# CC2538NF53 register map
File version: 1.0
CPU: CM3 1.0, other endian, MPU, FPU, 3 interrupt priority bits
Registers are 32-bit, read-write, reset 0x0 unless marked. A register's access mark holds for its fields unless they carry their own. Offsets are from the block's base; [hi:lo] are bit positions; {n}, {i} and the like mark numbered series.

## ANA_REGS — Register fields should be considered static unless otherwise noted as dynamic.
Base 0x400D6000
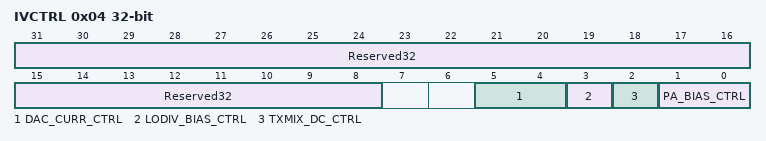
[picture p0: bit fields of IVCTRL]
0x04 IVCTRL — Analog control register
  [31:8] Reserved32 — [31:8] This register is 8 bits in a 32-bit address space.
  [5:4] DAC_CURR_CTRL — [5:4] Controls bias current to DAC 00: 100% IVREF, 0% IREF bias 01: 60% IVREF, 40% IREF bias 10: 40% IVREF, 60% IREF bias 11: 0% IVREF, 100% IREF bias
  [3] LODIV_BIAS_CTRL — [3:3] Controls bias current to LODIV 1: PTAT bias 0: IVREF bias
  [2] TXMIX_DC_CTRL — [2:2] Controls DC bias in TXMIX
  [1:0] PA_BIAS_CTRL — [1:0] Controls bias current to PA 00: IREF bias 01: IREF and IVREF bias (CC2530 mode) 10: PTAT bias 11: Increased PTAT slope bias

## STTEST — Register fields should be considered static unless otherwise noted as dynamic.
Base 0x40110000
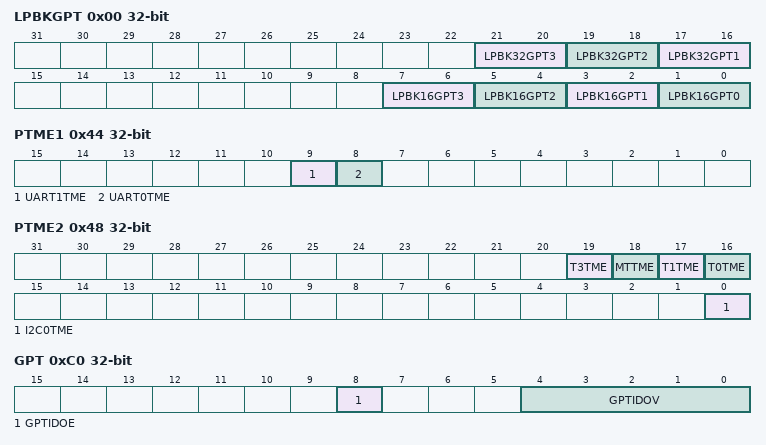
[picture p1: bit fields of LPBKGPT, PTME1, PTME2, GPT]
0x00 LPBKGPT — GPTIMER Internal loopback
  [21:20] LPBK32GPT3 — [21:20] GPTimer3 32-bit RTC loopback modes 00: Normal operation 01: GPT0 GPTimerA PWM connected to GPT3 capture 10: GPT0 capture connected to GPT3 PWM GPTimer A 11: Reserved, defaults to normal operation
  [19:18] LPBK32GPT2 — [19:18] GPTimer2 32-bit RTC loopback modes 00: Normal operation 01: GPT0 Timer A PWM connected to GPT2 capture 10: GPT0 capture connected to GPT2 PWM Timer A 11: Reserved, defaults to normal operation
  [17:16] LPBK32GPT1 — [17:16] GPTimer1 32-bit RTC loopback modes 00: Normal operation 01: GPT0 timerA PWM connected to GPT1 capture 10: GPT0 capture connected to GPT1 PWM Timer A 11: Reserved, defaults to normal operation
  [2n+1:2n] LPBK16GPT{n} (n=0..3) — [{2n+1}:{2n}] GPTimer{n} 16-bit loopback modes 00: Normal operation 01: Timer A PWM connected to Timer B capture 10: Timer A capture connected to Timer B PWM 11: Reserved, defaults to normal operation
0x04 LPBKUART — UART internal loopback
  [0] LPBKUART — [0:0] UART0/1 loopback mode 0: Normal operation 1: UART0 TX (RX) connected to UART1 RX (TX)
0x0C LPBKI2C — I2C internal loopback
  [0] LPBKI2C — [0:0] I2C0 Master/slave loopback mode 0: Normal mode
0x44 PTME1 — Peripheral test mode enable 1
  [9] UART1TME — [9:9] UART1 test mode enable
  [8] UART0TME — [8:8] UART0 test mode enable
0x48 PTME2 — Peripheral test mode enable 2
  [19] T3TME — [19:19] Timer3 test mode enable
  [18] MTTME — [18:18] MacTimer test mode enable
  [17] T1TME — [17:17] Timer1 test mode enable
  [16] T0TME — [16:16] Timer0 test mode enable
  [0] I2C0TME — [0:0] I2C 0 test mode enable
0xC0 GPT — GPTIMER override values
  [8] GPTIDOE — [8:8] GPTimer increment/decrement override enable
  [4:0] GPTIDOV — [4:0] GPTimer increment/decrement override value

## CCTEST — Register fields should be considered static unless otherwise noted as dynamic.
Base 0x44010000
0x00 IO — Output strength control
  [0] SC — [0:0] I/O strength control bit Common to all digital output pads Should be set when unregulated voltage is below approximately 2.6 V.
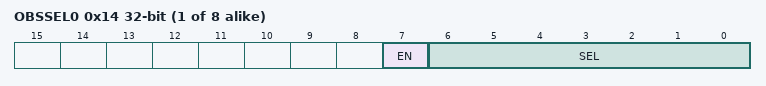
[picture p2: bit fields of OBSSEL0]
{0x14+4i} OBSSEL{i} (i=0..7) — Select output signal on observation output {i}
  [7] EN — [7:7] Observation output {i} enable control for PC{i} 0: Observation output disabled 1: Observation output enabled Note: If enabled, this overwrites the standard GPIO behavior of PC{i}.
  [6:0] SEL — [6:0] n - obs_sigs[n] output on output {i}: 0: rfc_obs_sig0 1: rfc_obs_sig1 2: rfc_obs_sig2 Others: Reserved
0x34 TR0 — Test register 0
  [1] ADCTM — [1:1] Set to 1 to connect the temperature sensor to the SOC_ADC. See also RFCORE_XREG_ATEST register description to enable the temperature sensor.
0x50 USBCTRL — USB PHY stand-by control
  [0] USB_STB — [0:0] USB PHY stand-by override bit When this bit is cleared to 0 (default state) the USB module cannot change the stand-by mode of the PHY (USB pads) and the PHY is forced out of stand-by mode. This bit must be 1 as well as the stand-by control from the USB controller, before the mode of the PHY is stand-by.
